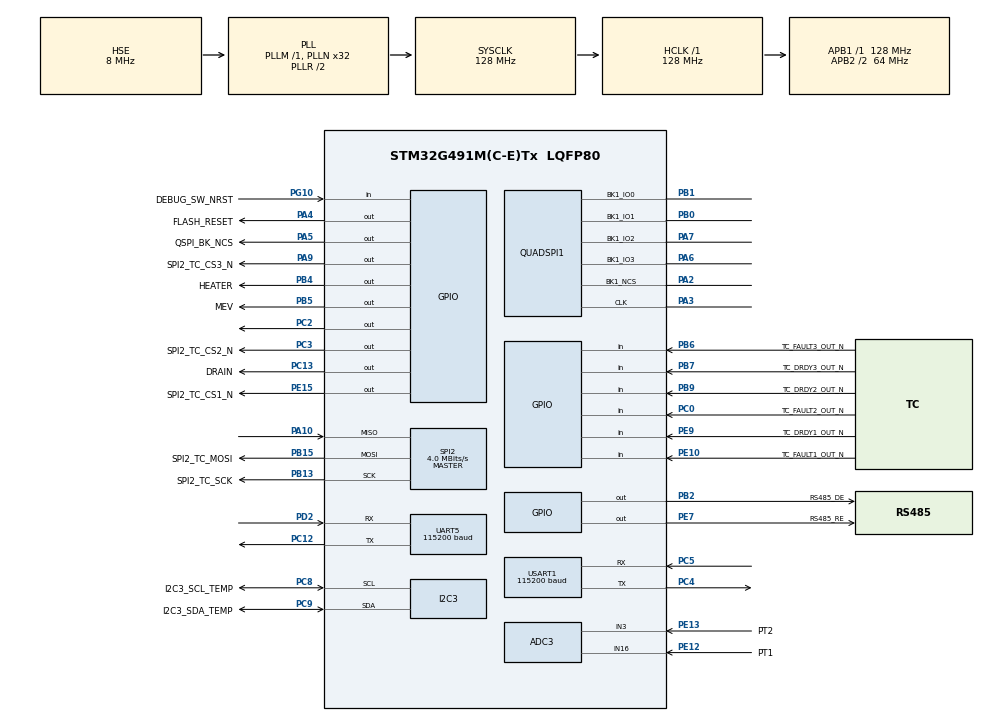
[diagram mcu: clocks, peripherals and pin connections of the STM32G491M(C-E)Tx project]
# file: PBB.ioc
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ADC3.Channel-0\#ChannelRegularConversion=ADC_CHANNEL_3
ADC3.Channel-1\#ChannelRegularConversion=ADC_CHANNEL_16
ADC3.ClockPrescaler=ADC_CLOCK_ASYNC_DIV4
ADC3.ContinuousConvMode=ENABLE
ADC3.GainCompensation=0
ADC3.NbrOfConversion=2
ADC3.NbrOfConversionFlag=1
ADC3.OffsetNumber-0\#ChannelRegularConversion=ADC_OFFSET_NONE
ADC3.OffsetNumber-1\#ChannelRegularConversion=ADC_OFFSET_NONE
ADC3.OversamplingMode=ENABLE
ADC3.Rank-0\#ChannelRegularConversion=1
ADC3.Rank-1\#ChannelRegularConversion=2
ADC3.Ratio=ADC_OVERSAMPLING_RATIO_64
ADC3.RightBitShift=ADC_RIGHTBITSHIFT_4
ADC3.SamplingTime-0\#ChannelRegularConversion=ADC_SAMPLETIME_247CYCLES_5
ADC3.SamplingTime-1\#ChannelRegularConversion=ADC_SAMPLETIME_247CYCLES_5
ADC3.master=1
FREERTOS.Tasks01=defaultTask,0,192,StartDefaultTask,Default,NULL,Dynamic,NULL,NULL
FREERTOS.configMINIMAL_STACK_SIZE=192
FREERTOS.configTOTAL_HEAP_SIZE=100000
FREERTOS.configUSE_NEWLIB_REENTRANT=1
FREERTOS.configUSE_TIMERS=1
I2C3.Timing=0x20A0C4DF
Mcu.Family=STM32G4
Mcu.Name=STM32G491M(C-E)Tx
Mcu.Package=LQFP80
NVIC.PriorityGroup=NVIC_PRIORITYGROUP_4
NVIC.TIM2_IRQn=true\:15\:0\:false\:false\:true\:false\:false\:true\:true
NVIC.TimeBase=TIM2_IRQn
NVIC.TimeBaseIP=TIM2
NVIC.UART5_IRQn=true\:5\:0\:false\:false\:true\:true\:true\:true\:true
NVIC.USART1_IRQn=true\:5\:0\:false\:false\:true\:true\:true\:true\:true
PA10.Mode=Full_Duplex_Master
PA10.Signal=SPI2_MISO
PA13.Mode=JTAG_4_pins
PA13.Signal=SYS_JTMS-SWDIO
PA14.Mode=JTAG_4_pins
PA14.Signal=SYS_JTCK-SWCLK
PA15.Mode=JTAG_4_pins
PA15.Signal=SYS_JTDI
PA2.Mode=Single Bank 1
PA2.Signal=QUADSPI1_BK1_NCS
PA3.Mode=Single Bank 1
PA3.Signal=QUADSPI1_CLK
PA4.GPIO_Label=FLASH_RESET
PA4.Signal=GPIO_Output
PA5.GPIO_Label=QSPI_BK_NCS
PA5.GPIO_Speed=GPIO_SPEED_FREQ_VERY_HIGH
PA5.PinState=GPIO_PIN_SET
PA5.Signal=GPIO_Output
PA6.Mode=Single Bank 1
PA6.Signal=QUADSPI1_BK1_IO3
PA7.Mode=Single Bank 1
PA7.Signal=QUADSPI1_BK1_IO2
PA9.GPIO_Label=SPI2_TC_CS3_N
PA9.Signal=GPIO_Output
PB0.Mode=Single Bank 1
PB0.Signal=QUADSPI1_BK1_IO1
PB1.Mode=Single Bank 1
PB1.Signal=QUADSPI1_BK1_IO0
PB13.GPIO_Label=SPI2_TC_SCK
PB13.Mode=Full_Duplex_Master
PB13.Signal=SPI2_SCK
PB15.GPIO_Label=SPI2_TC_MOSI
PB15.Mode=Full_Duplex_Master
PB15.Signal=SPI2_MOSI
PB2.GPIO_Label=RS485_DE
PB2.Signal=GPIO_Output
PB3.Mode=JTAG_4_pins
PB3.Signal=SYS_JTDO-SWO
PB4.GPIO_Label=HEATER
PB4.Signal=GPIO_Output
PB5.GPIO_Label=MEV
PB5.Signal=GPIO_Output
PB6.GPIO_Label=TC_FAULT3_OUT_N
PB6.Signal=GPIO_Input
PB7.GPIO_Label=TC_DRDY3_OUT_N
PB7.Signal=GPIO_Input
PB9.GPIO_Label=TC_DRDY2_OUT_N
PB9.Signal=GPIO_Input
PC0.GPIO_Label=TC_FAULT2_OUT_N
PC0.Signal=GPIO_Input
PC12.Mode=Asynchronous
PC12.Signal=UART5_TX
PC13.GPIO_Label=DRAIN
PC13.Signal=GPIO_Output
PC2.Signal=GPIO_Output
PC3.GPIO_Label=SPI2_TC_CS2_N
PC3.Signal=GPIO_Output
PC4.Mode=Asynchronous
PC4.Signal=USART1_TX
PC5.Mode=Asynchronous
PC5.Signal=USART1_RX
PC8.GPIO_Label=I2C3_SCL_TEMP
PC8.Mode=I2C
PC8.Signal=I2C3_SCL
PC9.GPIO_Label=I2C3_SDA_TEMP
PC9.Mode=I2C
PC9.Signal=I2C3_SDA
PD2.Mode=Asynchronous
PD2.Signal=UART5_RX
PE10.GPIO_Label=TC_FAULT1_OUT_N
PE10.Signal=GPIO_Input
PE12.GPIO_Label=PT1
PE12.Mode=IN16-Single-Ended
PE12.Signal=ADC3_IN16
PE13.GPIO_Label=PT2
PE13.Mode=IN3-Single-Ended
PE13.Signal=ADC3_IN3
PE15.GPIO_Label=SPI2_TC_CS1_N
PE15.Signal=GPIO_Output
PE7.GPIO_Label=RS485_RE
PE7.Signal=GPIO_Output
PE9.GPIO_Label=TC_DRDY1_OUT_N
PE9.Signal=GPIO_Input
PF0-OSC_IN.Mode=HSE-External-Oscillator
PF0-OSC_IN.Signal=RCC_OSC_IN
PF1-OSC_OUT.Mode=HSE-External-Oscillator
PF1-OSC_OUT.Signal=RCC_OSC_OUT
PG10-NRST.GPIO_Label=DEBUG_SW_NRST
PG10-NRST.Signal=GPIO_Input
ProjectManager.HeapSize=0x200
ProjectManager.StackSize=0x400
ProjectManager.TargetToolchain=STM32CubeIDE
QUADSPI1.ChipSelectHighTime=QSPI_CS_HIGH_TIME_1_CYCLE
QUADSPI1.ClockMode=QSPI_CLOCK_MODE_0
QUADSPI1.ClockPrescaler=8
QUADSPI1.FifoThreshold=4
QUADSPI1.FlashSize=25
QUADSPI1.SampleShifting=QSPI_SAMPLE_SHIFTING_NONE
RCC.ADC12Freq_Value=128000000
RCC.ADC345Freq_Value=128000000
RCC.AHBFreq_Value=128000000
RCC.APB1Freq_Value=128000000
RCC.APB1TimFreq_Value=128000000
RCC.APB2CLKDivider=RCC_HCLK_DIV2
RCC.APB2Freq_Value=64000000
RCC.APB2TimFreq_Value=128000000
RCC.CortexFreq_Value=128000000
RCC.EXTERNAL_CLOCK_VALUE=12288000
RCC.HCLKFreq_Value=128000000
RCC.HSE_VALUE=8000000
RCC.HSI48_VALUE=48000000
RCC.HSI_VALUE=16000000
RCC.LSE_VALUE=32768
RCC.PLLN=32
RCC.PLLSourceVirtual=RCC_PLLSOURCE_HSE
RCC.QSPICLockSelection=RCC_QSPICLKSOURCE_PLL
RCC.SYSCLKFreq_VALUE=128000000
RCC.SYSCLKSource=RCC_SYSCLKSOURCE_PLLCLK
RCC.USBFreq_Value=48000000
RCC.VCOOutputFreq_Value=256000000
SPI2.BaudRatePrescaler=SPI_BAUDRATEPRESCALER_32
SPI2.CLKPhase=SPI_PHASE_2EDGE
SPI2.CLKPolarity=SPI_POLARITY_HIGH
SPI2.CalculateBaudRate=4.0 MBits/s
SPI2.Direction=SPI_DIRECTION_2LINES
SPI2.Mode=SPI_MODE_MASTER
SPI2.VirtualType=VM_MASTER
UART5.BaudRate=115200
USART1.BaudRate=115200
USART1.VirtualMode-Asynchronous=VM_ASYNC
VP_CRC_VS_CRC.Mode=CRC_Activate
VP_FREERTOS_VS_CMSIS_V1.Mode=CMSIS_V1
VP_SYS_VS_DBSignals.Mode=DisableDeadBatterySignals
VP_SYS_VS_tim2.Mode=TIM2
board=custom

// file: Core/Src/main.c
/* USER CODE BEGIN Header */
/**
  ******************************************************************************
  * @file           : main.c
  * @brief          : Main program body
  ******************************************************************************
  * @attention
  *
  * Copyright (c) 2026 STMicroelectronics.
  * All rights reserved.
  *
  * This software is licensed under terms that can be found in the LICENSE file
  * in the root directory of this software component.
  * If no LICENSE file comes with this software, it is provided AS-IS.
  *
  ******************************************************************************
  */
/* USER CODE END Header */
#include "main.h"
#include "cmsis_os.h"

/* USER CODE BEGIN Includes */
#include <RunInterface.hpp>
//#define USE_FULL_LL_DRIVER
/* USER CODE END Includes */

ADC_HandleTypeDef hadc3;

CRC_HandleTypeDef hcrc;

I2C_HandleTypeDef hi2c3;

QSPI_HandleTypeDef hqspi1;

SPI_HandleTypeDef hspi2;

osThreadId defaultTaskHandle;

void SystemClock_Config(void);
static void MX_GPIO_Init(void);
static void MX_CRC_Init(void);
static void MX_QUADSPI1_Init(void);
static void MX_USART1_UART_Init(void);
static void MX_UART5_Init(void);
static void MX_I2C3_Init(void);
static void MX_SPI2_Init(void);
static void MX_ADC3_Init(void);
void StartDefaultTask(void const * argument);

int main(void)
{
  /* USER CODE BEGIN 1 */
	SCB-> VTOR = FLASH_BASE;
  /* USER CODE END 1 */

  /* MCU Configuration--------------------------------------------------------*/

  /* Reset of all peripherals, Initializes the Flash interface and the Systick. */
  HAL_Init();

  /* Configure the system clock */
  SystemClock_Config();

  /* Initialize all configured peripherals */
  MX_GPIO_Init();
  MX_CRC_Init();
  MX_QUADSPI1_Init();
  MX_USART1_UART_Init();
  MX_UART5_Init();
  MX_I2C3_Init();
  MX_SPI2_Init();
  MX_ADC3_Init();
  /* USER CODE BEGIN 2 */
//  HAL_ADCEx_Calibration_Start(&hadc3, ADC_SINGLE_ENDED);
  __enable_irq();

  run_interface();

#if 0

  /* USER CODE END 2 */

  /* Create the thread(s) */
  /* definition and creation of defaultTask */
  osThreadDef(defaultTask, StartDefaultTask, osPriorityNormal, 0, 192);
  defaultTaskHandle = osThreadCreate(osThread(defaultTask), NULL);

  /* Start scheduler */
  osKernelStart();

  /* We should never get here as control is now taken by the scheduler */
  /* Infinite loop */
  while (1)
  {

    /* USER CODE BEGIN 3 */
  }
#endif
  /* USER CODE END 3 */
}

void SystemClock_Config(void)
{
  RCC_OscInitTypeDef RCC_OscInitStruct = {0};
  RCC_ClkInitTypeDef RCC_ClkInitStruct = {0};

  /** Configure the main internal regulator output voltage
  */
  HAL_PWREx_ControlVoltageScaling(PWR_REGULATOR_VOLTAGE_SCALE1);

  /** Initializes the RCC Oscillators according to the specified parameters
  * in the RCC_OscInitTypeDef structure.
  */
  RCC_OscInitStruct.OscillatorType = RCC_OSCILLATORTYPE_HSE;
  RCC_OscInitStruct.HSEState = RCC_HSE_ON;
  RCC_OscInitStruct.PLL.PLLState = RCC_PLL_ON;
  RCC_OscInitStruct.PLL.PLLSource = RCC_PLLSOURCE_HSE;
  RCC_OscInitStruct.PLL.PLLM = RCC_PLLM_DIV1;
  RCC_OscInitStruct.PLL.PLLN = 32;
  RCC_OscInitStruct.PLL.PLLP = RCC_PLLP_DIV2;
  RCC_OscInitStruct.PLL.PLLQ = RCC_PLLQ_DIV2;
  RCC_OscInitStruct.PLL.PLLR = RCC_PLLR_DIV2;
  if (HAL_RCC_OscConfig(&RCC_OscInitStruct) != HAL_OK)
  {
    Error_Handler();
  }

  /** Initializes the CPU, AHB and APB buses clocks
  */
  RCC_ClkInitStruct.ClockType = RCC_CLOCKTYPE_HCLK|RCC_CLOCKTYPE_SYSCLK
                              |RCC_CLOCKTYPE_PCLK1|RCC_CLOCKTYPE_PCLK2;
  RCC_ClkInitStruct.SYSCLKSource = RCC_SYSCLKSOURCE_PLLCLK;
  RCC_ClkInitStruct.AHBCLKDivider = RCC_SYSCLK_DIV1;
  RCC_ClkInitStruct.APB1CLKDivider = RCC_HCLK_DIV1;
  RCC_ClkInitStruct.APB2CLKDivider = RCC_HCLK_DIV2;

  if (HAL_RCC_ClockConfig(&RCC_ClkInitStruct, FLASH_LATENCY_1) != HAL_OK)
  {
    Error_Handler();
  }
}

static void MX_ADC3_Init(void)
{

  ADC_ChannelConfTypeDef sConfig = {0};

  /** Common config
  */
  hadc3.Instance = ADC3;
  hadc3.Init.ClockPrescaler = ADC_CLOCK_ASYNC_DIV4;
  hadc3.Init.Resolution = ADC_RESOLUTION_12B;
  hadc3.Init.DataAlign = ADC_DATAALIGN_RIGHT;
  hadc3.Init.GainCompensation = 0;
  hadc3.Init.ScanConvMode = ADC_SCAN_ENABLE;
  hadc3.Init.EOCSelection = ADC_EOC_SINGLE_CONV;
  hadc3.Init.LowPowerAutoWait = DISABLE;
  hadc3.Init.ContinuousConvMode = ENABLE;
  hadc3.Init.NbrOfConversion = 2;
  hadc3.Init.DiscontinuousConvMode = DISABLE;
  hadc3.Init.ExternalTrigConv = ADC_SOFTWARE_START;
  hadc3.Init.ExternalTrigConvEdge = ADC_EXTERNALTRIGCONVEDGE_NONE;
  hadc3.Init.DMAContinuousRequests = DISABLE;
  hadc3.Init.Overrun = ADC_OVR_DATA_PRESERVED;
  hadc3.Init.OversamplingMode = ENABLE;
  hadc3.Init.Oversampling.Ratio = ADC_OVERSAMPLING_RATIO_64;
  hadc3.Init.Oversampling.RightBitShift = ADC_RIGHTBITSHIFT_4;
  hadc3.Init.Oversampling.TriggeredMode = ADC_TRIGGEREDMODE_SINGLE_TRIGGER;
  hadc3.Init.Oversampling.OversamplingStopReset = ADC_REGOVERSAMPLING_CONTINUED_MODE;
  if (HAL_ADC_Init(&hadc3) != HAL_OK)
  {
    Error_Handler();
  }

  /** Configure Regular Channel
  */
  sConfig.Channel = ADC_CHANNEL_3;
  sConfig.Rank = ADC_REGULAR_RANK_1;
  sConfig.SamplingTime = ADC_SAMPLETIME_247CYCLES_5;
  sConfig.SingleDiff = ADC_SINGLE_ENDED;
  sConfig.OffsetNumber = ADC_OFFSET_NONE;
  sConfig.Offset = 0;
  if (HAL_ADC_ConfigChannel(&hadc3, &sConfig) != HAL_OK)
  {
    Error_Handler();
  }

  /** Configure Regular Channel
  */
  sConfig.Channel = ADC_CHANNEL_16;
  sConfig.Rank = ADC_REGULAR_RANK_2;
  if (HAL_ADC_ConfigChannel(&hadc3, &sConfig) != HAL_OK)
  {
    Error_Handler();
  }

}

static void MX_CRC_Init(void)
{

  hcrc.Instance = CRC;
  hcrc.Init.DefaultPolynomialUse = DEFAULT_POLYNOMIAL_ENABLE;
  hcrc.Init.DefaultInitValueUse = DEFAULT_INIT_VALUE_ENABLE;
  hcrc.Init.InputDataInversionMode = CRC_INPUTDATA_INVERSION_NONE;
  hcrc.Init.OutputDataInversionMode = CRC_OUTPUTDATA_INVERSION_DISABLE;
  hcrc.InputDataFormat = CRC_INPUTDATA_FORMAT_BYTES;
  if (HAL_CRC_Init(&hcrc) != HAL_OK)
  {
    Error_Handler();
  }

}

static void MX_I2C3_Init(void)
{

  hi2c3.Instance = I2C3;
  hi2c3.Init.Timing = 0x20A0C4DF;
  hi2c3.Init.OwnAddress1 = 0;
  hi2c3.Init.AddressingMode = I2C_ADDRESSINGMODE_7BIT;
  hi2c3.Init.DualAddressMode = I2C_DUALADDRESS_DISABLE;
  hi2c3.Init.OwnAddress2 = 0;
  hi2c3.Init.OwnAddress2Masks = I2C_OA2_NOMASK;
  hi2c3.Init.GeneralCallMode = I2C_GENERALCALL_DISABLE;
  hi2c3.Init.NoStretchMode = I2C_NOSTRETCH_DISABLE;
  if (HAL_I2C_Init(&hi2c3) != HAL_OK)
  {
    Error_Handler();
  }

  /** Configure Analogue filter
  */
  if (HAL_I2CEx_ConfigAnalogFilter(&hi2c3, I2C_ANALOGFILTER_ENABLE) != HAL_OK)
  {
    Error_Handler();
  }

  /** Configure Digital filter
  */
  if (HAL_I2CEx_ConfigDigitalFilter(&hi2c3, 0) != HAL_OK)
  {
    Error_Handler();
  }

}

static void MX_QUADSPI1_Init(void)
{

  /* QUADSPI1 parameter configuration*/
  hqspi1.Instance = QUADSPI;
  hqspi1.Init.ClockPrescaler = 8;
  hqspi1.Init.FifoThreshold = 4;
  hqspi1.Init.SampleShifting = QSPI_SAMPLE_SHIFTING_NONE;
  hqspi1.Init.FlashSize = 25;
  hqspi1.Init.ChipSelectHighTime = QSPI_CS_HIGH_TIME_1_CYCLE;
  hqspi1.Init.ClockMode = QSPI_CLOCK_MODE_0;
  hqspi1.Init.FlashID = QSPI_FLASH_ID_1;
  hqspi1.Init.DualFlash = QSPI_DUALFLASH_DISABLE;
  if (HAL_QSPI_Init(&hqspi1) != HAL_OK)
  {
    Error_Handler();
  }

}

static void MX_SPI2_Init(void)
{

  /* SPI2 parameter configuration*/
  hspi2.Instance = SPI2;
  hspi2.Init.Mode = SPI_MODE_MASTER;
  hspi2.Init.Direction = SPI_DIRECTION_2LINES;
  hspi2.Init.DataSize = SPI_DATASIZE_8BIT;
  hspi2.Init.CLKPolarity = SPI_POLARITY_HIGH;
  hspi2.Init.CLKPhase = SPI_PHASE_2EDGE;
  hspi2.Init.NSS = SPI_NSS_SOFT;
  hspi2.Init.BaudRatePrescaler = SPI_BAUDRATEPRESCALER_32;
  hspi2.Init.FirstBit = SPI_FIRSTBIT_MSB;
  hspi2.Init.TIMode = SPI_TIMODE_DISABLE;
  hspi2.Init.CRCCalculation = SPI_CRCCALCULATION_DISABLE;
  hspi2.Init.CRCPolynomial = 7;
  hspi2.Init.CRCLength = SPI_CRC_LENGTH_DATASIZE;
  hspi2.Init.NSSPMode = SPI_NSS_PULSE_DISABLE;
  if (HAL_SPI_Init(&hspi2) != HAL_OK)
  {
    Error_Handler();
  }

}

static void MX_UART5_Init(void)
{

  LL_USART_InitTypeDef USART_InitStruct = {0};

  LL_GPIO_InitTypeDef GPIO_InitStruct = {0};
  RCC_PeriphCLKInitTypeDef PeriphClkInit = {0};

  /** Initializes the peripherals clocks
  */
  PeriphClkInit.PeriphClockSelection = RCC_PERIPHCLK_UART5;
  PeriphClkInit.Uart5ClockSelection = RCC_UART5CLKSOURCE_PCLK1;
  if (HAL_RCCEx_PeriphCLKConfig(&PeriphClkInit) != HAL_OK)
  {
    Error_Handler();
  }

  /* Peripheral clock enable */
  LL_APB1_GRP1_EnableClock(LL_APB1_GRP1_PERIPH_UART5);

  LL_AHB2_GRP1_EnableClock(LL_AHB2_GRP1_PERIPH_GPIOC);
  LL_AHB2_GRP1_EnableClock(LL_AHB2_GRP1_PERIPH_GPIOD);
  /**UART5 GPIO Configuration
  PC12   ------> UART5_TX
  PD2   ------> UART5_RX
  */
  GPIO_InitStruct.Pin = LL_GPIO_PIN_12;
  GPIO_InitStruct.Mode = LL_GPIO_MODE_ALTERNATE;
  GPIO_InitStruct.Speed = LL_GPIO_SPEED_FREQ_LOW;
  GPIO_InitStruct.OutputType = LL_GPIO_OUTPUT_PUSHPULL;
  GPIO_InitStruct.Pull = LL_GPIO_PULL_NO;
  GPIO_InitStruct.Alternate = LL_GPIO_AF_5;
  LL_GPIO_Init(GPIOC, &GPIO_InitStruct);

  GPIO_InitStruct.Pin = LL_GPIO_PIN_2;
  GPIO_InitStruct.Mode = LL_GPIO_MODE_ALTERNATE;
  GPIO_InitStruct.Speed = LL_GPIO_SPEED_FREQ_LOW;
  GPIO_InitStruct.OutputType = LL_GPIO_OUTPUT_PUSHPULL;
  GPIO_InitStruct.Pull = LL_GPIO_PULL_NO;
  GPIO_InitStruct.Alternate = LL_GPIO_AF_5;
  LL_GPIO_Init(GPIOD, &GPIO_InitStruct);

  /* UART5 interrupt Init */
  NVIC_SetPriority(UART5_IRQn, NVIC_EncodePriority(NVIC_GetPriorityGrouping(),5, 0));
  NVIC_EnableIRQ(UART5_IRQn);

  USART_InitStruct.PrescalerValue = LL_USART_PRESCALER_DIV1;
  USART_InitStruct.BaudRate = 115200;
  USART_InitStruct.DataWidth = LL_USART_DATAWIDTH_8B;
  USART_InitStruct.StopBits = LL_USART_STOPBITS_1;
  USART_InitStruct.Parity = LL_USART_PARITY_NONE;
  USART_InitStruct.TransferDirection = LL_USART_DIRECTION_TX_RX;
  USART_InitStruct.HardwareFlowControl = LL_USART_HWCONTROL_NONE;
  USART_InitStruct.OverSampling = LL_USART_OVERSAMPLING_16;
  LL_USART_Init(UART5, &USART_InitStruct);
  LL_USART_DisableFIFO(UART5);
  LL_USART_SetTXFIFOThreshold(UART5, LL_USART_FIFOTHRESHOLD_1_8);
  LL_USART_SetRXFIFOThreshold(UART5, LL_USART_FIFOTHRESHOLD_1_8);
  LL_USART_ConfigAsyncMode(UART5);

  LL_USART_Enable(UART5);

  /* Polling UART5 initialisation */
  while((!(LL_USART_IsActiveFlag_TEACK(UART5))) || (!(LL_USART_IsActiveFlag_REACK(UART5))))
  {
  }

}

static void MX_USART1_UART_Init(void)
{

  LL_USART_InitTypeDef USART_InitStruct = {0};

  LL_GPIO_InitTypeDef GPIO_InitStruct = {0};
  RCC_PeriphCLKInitTypeDef PeriphClkInit = {0};

  /** Initializes the peripherals clocks
  */
  PeriphClkInit.PeriphClockSelection = RCC_PERIPHCLK_USART1;
  PeriphClkInit.Usart1ClockSelection = RCC_USART1CLKSOURCE_PCLK2;
  if (HAL_RCCEx_PeriphCLKConfig(&PeriphClkInit) != HAL_OK)
  {
    Error_Handler();
  }

  /* Peripheral clock enable */
  LL_APB2_GRP1_EnableClock(LL_APB2_GRP1_PERIPH_USART1);

  LL_AHB2_GRP1_EnableClock(LL_AHB2_GRP1_PERIPH_GPIOC);
  /**USART1 GPIO Configuration
  PC4   ------> USART1_TX
  PC5   ------> USART1_RX
  */
  GPIO_InitStruct.Pin = LL_GPIO_PIN_4;
  GPIO_InitStruct.Mode = LL_GPIO_MODE_ALTERNATE;
  GPIO_InitStruct.Speed = LL_GPIO_SPEED_FREQ_LOW;
  GPIO_InitStruct.OutputType = LL_GPIO_OUTPUT_PUSHPULL;
  GPIO_InitStruct.Pull = LL_GPIO_PULL_NO;
  GPIO_InitStruct.Alternate = LL_GPIO_AF_7;
  LL_GPIO_Init(GPIOC, &GPIO_InitStruct);

  GPIO_InitStruct.Pin = LL_GPIO_PIN_5;
  GPIO_InitStruct.Mode = LL_GPIO_MODE_ALTERNATE;
  GPIO_InitStruct.Speed = LL_GPIO_SPEED_FREQ_LOW;
  GPIO_InitStruct.OutputType = LL_GPIO_OUTPUT_PUSHPULL;
  GPIO_InitStruct.Pull = LL_GPIO_PULL_NO;
  GPIO_InitStruct.Alternate = LL_GPIO_AF_7;
  LL_GPIO_Init(GPIOC, &GPIO_InitStruct);

  /* USART1 interrupt Init */
  NVIC_SetPriority(USART1_IRQn, NVIC_EncodePriority(NVIC_GetPriorityGrouping(),5, 0));
  NVIC_EnableIRQ(USART1_IRQn);

  USART_InitStruct.PrescalerValue = LL_USART_PRESCALER_DIV1;
  USART_InitStruct.BaudRate = 115200;
  USART_InitStruct.DataWidth = LL_USART_DATAWIDTH_8B;
  USART_InitStruct.StopBits = LL_USART_STOPBITS_1;
  USART_InitStruct.Parity = LL_USART_PARITY_NONE;
  USART_InitStruct.TransferDirection = LL_USART_DIRECTION_TX_RX;
  USART_InitStruct.HardwareFlowControl = LL_USART_HWCONTROL_NONE;
  USART_InitStruct.OverSampling = LL_USART_OVERSAMPLING_16;
  LL_USART_Init(USART1, &USART_InitStruct);
  LL_USART_SetTXFIFOThreshold(USART1, LL_USART_FIFOTHRESHOLD_1_8);
  LL_USART_SetRXFIFOThreshold(USART1, LL_USART_FIFOTHRESHOLD_1_8);
  LL_USART_DisableFIFO(USART1);
  LL_USART_ConfigAsyncMode(USART1);

  LL_USART_Enable(USART1);

  /* Polling USART1 initialisation */
  while((!(LL_USART_IsActiveFlag_TEACK(USART1))) || (!(LL_USART_IsActiveFlag_REACK(USART1))))
  {
  }

}

static void MX_GPIO_Init(void)
{
  GPIO_InitTypeDef GPIO_InitStruct = {0};

  /* GPIO Ports Clock Enable */
  __HAL_RCC_GPIOC_CLK_ENABLE();
  __HAL_RCC_GPIOF_CLK_ENABLE();
  __HAL_RCC_GPIOG_CLK_ENABLE();
  __HAL_RCC_GPIOA_CLK_ENABLE();
  __HAL_RCC_GPIOB_CLK_ENABLE();
  __HAL_RCC_GPIOE_CLK_ENABLE();
  __HAL_RCC_GPIOD_CLK_ENABLE();

  /*Configure GPIO pin Output Level */
  HAL_GPIO_WritePin(GPIOC, DRAIN_Pin|GPIO_PIN_2|SPI2_TC_CS2_N_Pin, GPIO_PIN_RESET);

  /*Configure GPIO pin Output Level */
  HAL_GPIO_WritePin(GPIOA, FLASH_RESET_Pin|SPI2_TC_CS3_N_Pin, GPIO_PIN_RESET);

  /*Configure GPIO pin Output Level */
  HAL_GPIO_WritePin(QSPI_BK_NCS_GPIO_Port, QSPI_BK_NCS_Pin, GPIO_PIN_SET);

  /*Configure GPIO pin Output Level */
  HAL_GPIO_WritePin(GPIOB, RS485_DE_Pin|HEATER_Pin|MEV_Pin, GPIO_PIN_RESET);

  /*Configure GPIO pin Output Level */
  HAL_GPIO_WritePin(GPIOE, RS485_RE_Pin|SPI2_TC_CS1_N_Pin, GPIO_PIN_RESET);

  /*Configure GPIO pins : DRAIN_Pin PC2 SPI2_TC_CS2_N_Pin */
  GPIO_InitStruct.Pin = DRAIN_Pin|GPIO_PIN_2|SPI2_TC_CS2_N_Pin;
  GPIO_InitStruct.Mode = GPIO_MODE_OUTPUT_PP;
  GPIO_InitStruct.Pull = GPIO_NOPULL;
  GPIO_InitStruct.Speed = GPIO_SPEED_FREQ_LOW;
  HAL_GPIO_Init(GPIOC, &GPIO_InitStruct);

  /*Configure GPIO pin : DEBUG_SW_NRST_Pin */
  GPIO_InitStruct.Pin = DEBUG_SW_NRST_Pin;
  GPIO_InitStruct.Mode = GPIO_MODE_INPUT;
  GPIO_InitStruct.Pull = GPIO_NOPULL;
  HAL_GPIO_Init(DEBUG_SW_NRST_GPIO_Port, &GPIO_InitStruct);

  /*Configure GPIO pin : TC_FAULT2_OUT_N_Pin */
  GPIO_InitStruct.Pin = TC_FAULT2_OUT_N_Pin;
  GPIO_InitStruct.Mode = GPIO_MODE_INPUT;
  GPIO_InitStruct.Pull = GPIO_NOPULL;
  HAL_GPIO_Init(TC_FAULT2_OUT_N_GPIO_Port, &GPIO_InitStruct);

  /*Configure GPIO pins : FLASH_RESET_Pin SPI2_TC_CS3_N_Pin */
  GPIO_InitStruct.Pin = FLASH_RESET_Pin|SPI2_TC_CS3_N_Pin;
  GPIO_InitStruct.Mode = GPIO_MODE_OUTPUT_PP;
  GPIO_InitStruct.Pull = GPIO_NOPULL;
  GPIO_InitStruct.Speed = GPIO_SPEED_FREQ_LOW;
  HAL_GPIO_Init(GPIOA, &GPIO_InitStruct);

  /*Configure GPIO pin : QSPI_BK_NCS_Pin */
  GPIO_InitStruct.Pin = QSPI_BK_NCS_Pin;
  GPIO_InitStruct.Mode = GPIO_MODE_OUTPUT_PP;
  GPIO_InitStruct.Pull = GPIO_NOPULL;
  GPIO_InitStruct.Speed = GPIO_SPEED_FREQ_VERY_HIGH;
  HAL_GPIO_Init(QSPI_BK_NCS_GPIO_Port, &GPIO_InitStruct);

  /*Configure GPIO pins : RS485_DE_Pin HEATER_Pin MEV_Pin */
  GPIO_InitStruct.Pin = RS485_DE_Pin|HEATER_Pin|MEV_Pin;
  GPIO_InitStruct.Mode = GPIO_MODE_OUTPUT_PP;
  GPIO_InitStruct.Pull = GPIO_NOPULL;
  GPIO_InitStruct.Speed = GPIO_SPEED_FREQ_LOW;
  HAL_GPIO_Init(GPIOB, &GPIO_InitStruct);

  /*Configure GPIO pins : RS485_RE_Pin SPI2_TC_CS1_N_Pin */
  GPIO_InitStruct.Pin = RS485_RE_Pin|SPI2_TC_CS1_N_Pin;
  GPIO_InitStruct.Mode = GPIO_MODE_OUTPUT_PP;
  GPIO_InitStruct.Pull = GPIO_NOPULL;
  GPIO_InitStruct.Speed = GPIO_SPEED_FREQ_LOW;
  HAL_GPIO_Init(GPIOE, &GPIO_InitStruct);

  /*Configure GPIO pins : TC_DRDY1_OUT_N_Pin TC_FAULT1_OUT_N_Pin */
  GPIO_InitStruct.Pin = TC_DRDY1_OUT_N_Pin|TC_FAULT1_OUT_N_Pin;
  GPIO_InitStruct.Mode = GPIO_MODE_INPUT;
  GPIO_InitStruct.Pull = GPIO_NOPULL;
  HAL_GPIO_Init(GPIOE, &GPIO_InitStruct);

  /*Configure GPIO pins : TC_FAULT3_OUT_N_Pin TC_DRDY3_OUT_N_Pin TC_DRDY2_OUT_N_Pin */
  GPIO_InitStruct.Pin = TC_FAULT3_OUT_N_Pin|TC_DRDY3_OUT_N_Pin|TC_DRDY2_OUT_N_Pin;
  GPIO_InitStruct.Mode = GPIO_MODE_INPUT;
  GPIO_InitStruct.Pull = GPIO_NOPULL;
  HAL_GPIO_Init(GPIOB, &GPIO_InitStruct);

}

void StartDefaultTask(void const * argument)
{
  for(;;)
  {
    osDelay(1);
  }
}

void HAL_TIM_PeriodElapsedCallback(TIM_HandleTypeDef *htim)
{
  if (htim->Instance == TIM2) {
    HAL_IncTick();
  }
}

void Error_Handler(void)
{
  __disable_irq();
  while (1)
  {
  }
}
